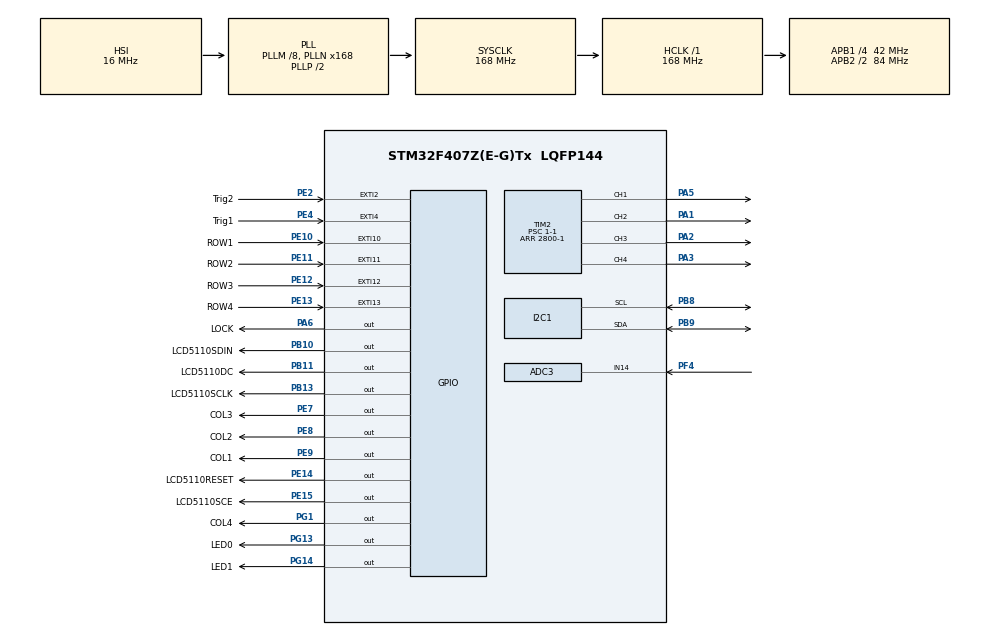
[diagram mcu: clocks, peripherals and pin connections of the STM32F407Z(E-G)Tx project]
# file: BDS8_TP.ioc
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ADC1.Channel-25\#ChannelRegularConversion=ADC_CHANNEL_VREFINT
ADC1.ClockPrescaler=ADC_CLOCK_SYNC_PCLK_DIV6
ADC1.ContinuousConvMode=ENABLE
ADC1.DMAContinuousRequests=ENABLE
ADC1.ExternalTrigConv=ADC_EXTERNALTRIGCONV_T3_TRGO
ADC1.ExternalTrigConvEdge=ADC_EXTERNALTRIGCONVEDGE_FALLING
ADC1.Mode=__NULL
ADC1.NbrOfConversionFlag=1
ADC1.Rank-25\#ChannelRegularConversion=1
ADC1.SamplingTime-25\#ChannelRegularConversion=ADC_SAMPLETIME_480CYCLES
ADC1.ScanConvMode=ENABLE
ADC1.master=1
ADC3.Channel-0\#ChannelRegularConversion=ADC_CHANNEL_14
ADC3.ClockPrescaler=ADC_CLOCK_SYNC_PCLK_DIV6
ADC3.DMAContinuousRequests=ENABLE
ADC3.ExternalTrigConv=ADC_EXTERNALTRIGCONV_T3_TRGO
ADC3.ExternalTrigConvEdge=ADC_EXTERNALTRIGCONVEDGE_FALLING
ADC3.NbrOfConversionFlag=1
ADC3.Rank-0\#ChannelRegularConversion=1
ADC3.SamplingTime-0\#ChannelRegularConversion=ADC_SAMPLETIME_480CYCLES
ADC3.ScanConvMode=ENABLE
Dma.ADC1.0.Direction=DMA_PERIPH_TO_MEMORY
Dma.ADC1.0.FIFOMode=DMA_FIFOMODE_DISABLE
Dma.ADC1.0.Instance=DMA2_Stream4
Dma.ADC1.0.MemDataAlignment=DMA_MDATAALIGN_WORD
Dma.ADC1.0.MemInc=DMA_MINC_ENABLE
Dma.ADC1.0.Mode=DMA_CIRCULAR
Dma.ADC1.0.PeriphDataAlignment=DMA_PDATAALIGN_WORD
Dma.ADC1.0.PeriphInc=DMA_PINC_DISABLE
Dma.ADC1.0.Priority=DMA_PRIORITY_VERY_HIGH
Dma.ADC3.1.Direction=DMA_PERIPH_TO_MEMORY
Dma.ADC3.1.FIFOMode=DMA_FIFOMODE_DISABLE
Dma.ADC3.1.Instance=DMA2_Stream0
Dma.ADC3.1.MemDataAlignment=DMA_MDATAALIGN_WORD
Dma.ADC3.1.MemInc=DMA_MINC_ENABLE
Dma.ADC3.1.Mode=DMA_CIRCULAR
Dma.ADC3.1.PeriphDataAlignment=DMA_PDATAALIGN_WORD
Dma.ADC3.1.PeriphInc=DMA_PINC_DISABLE
Dma.ADC3.1.Priority=DMA_PRIORITY_LOW
Dma.Request0=ADC1
Dma.Request1=ADC3
I2C1.I2C_Mode=I2C_Fast
Mcu.Family=STM32F4
Mcu.Name=STM32F407Z(E-G)Tx
Mcu.Package=LQFP144
NVIC.EXTI15_10_IRQn=true\:0\:0\:false\:false\:true\:true\:true
NVIC.EXTI2_IRQn=true\:0\:0\:false\:false\:true\:true\:true
NVIC.EXTI4_IRQn=true\:0\:0\:false\:false\:true\:true\:true
NVIC.PriorityGroup=NVIC_PRIORITYGROUP_2
NVIC.TIM2_IRQn=true\:0\:0\:false\:false\:true\:true\:true
NVIC.TIM3_IRQn=true\:1\:0\:true\:false\:true\:true\:true
PA1.GPIO_PuPd=GPIO_NOPULL
PA1.GPIO_Speed=GPIO_SPEED_FREQ_LOW
PA1.Signal=S_TIM2_CH2
PA13.Mode=Serial_Wire
PA13.Signal=SYS_JTMS-SWDIO
PA14.Mode=Serial_Wire
PA14.Signal=SYS_JTCK-SWCLK
PA2.GPIO_PuPd=GPIO_NOPULL
PA2.GPIO_Speed=GPIO_SPEED_FREQ_LOW
PA2.Signal=S_TIM2_CH3
PA3.Signal=S_TIM2_CH4
PA5.GPIO_PuPd=GPIO_NOPULL
PA5.GPIO_Speed=GPIO_SPEED_FREQ_LOW
PA5.Signal=S_TIM2_CH1_ETR
PA6.GPIO_Label=LOCK
PA6.PinState=GPIO_PIN_SET
PA6.Signal=GPIO_Output
PB10.GPIO_Label=LCD5110SDIN
PB10.GPIO_Speed=GPIO_SPEED_FREQ_VERY_HIGH
PB10.Signal=GPIO_Output
PB11.GPIO_Label=LCD5110DC
PB11.GPIO_Speed=GPIO_SPEED_FREQ_VERY_HIGH
PB11.Signal=GPIO_Output
PB13.GPIO_Label=LCD5110SCLK
PB13.GPIO_Speed=GPIO_SPEED_FREQ_VERY_HIGH
PB13.Signal=GPIO_Output
PB8.Mode=I2C
PB8.Signal=I2C1_SCL
PB9.Mode=I2C
PB9.Signal=I2C1_SDA
PC14-OSC32_IN.Mode=LSE-External-Oscillator
PC14-OSC32_IN.Signal=RCC_OSC32_IN
PC15-OSC32_OUT.Mode=LSE-External-Oscillator
PC15-OSC32_OUT.Signal=RCC_OSC32_OUT
PE10.GPIO_Label=ROW1
PE10.GPIO_ModeDefaultEXTI=GPIO_MODE_IT_FALLING
PE10.GPIO_PuPd=GPIO_PULLUP
PE10.Signal=GPXTI10
PE11.GPIO_Label=ROW2
PE11.GPIO_ModeDefaultEXTI=GPIO_MODE_IT_FALLING
PE11.GPIO_PuPd=GPIO_PULLUP
PE11.Signal=GPXTI11
PE12.GPIO_Label=ROW3
PE12.GPIO_ModeDefaultEXTI=GPIO_MODE_IT_FALLING
PE12.GPIO_PuPd=GPIO_PULLUP
PE12.Signal=GPXTI12
PE13.GPIO_Label=ROW4
PE13.GPIO_ModeDefaultEXTI=GPIO_MODE_IT_FALLING
PE13.GPIO_PuPd=GPIO_PULLUP
PE13.Signal=GPXTI13
PE14.GPIO_Label=LCD5110RESET
PE14.GPIO_Speed=GPIO_SPEED_FREQ_VERY_HIGH
PE14.Signal=GPIO_Output
PE15.GPIO_Label=LCD5110SCE
PE15.GPIO_PuPd=GPIO_PULLUP
PE15.GPIO_Speed=GPIO_SPEED_FREQ_VERY_HIGH
PE15.PinState=GPIO_PIN_SET
PE15.Signal=GPIO_Output
PE2.GPIO_Label=Trig2
PE2.GPIO_ModeDefaultEXTI=GPIO_MODE_IT_RISING
PE2.GPIO_PuPd=GPIO_PULLDOWN
PE2.Signal=GPXTI2
PE4.GPIO_Label=Trig1
PE4.GPIO_ModeDefaultEXTI=GPIO_MODE_IT_RISING
PE4.GPIO_PuPd=GPIO_PULLDOWN
PE4.Signal=GPXTI4
PE7.GPIO_Label=COL3
PE7.GPIO_PuPd=GPIO_PULLDOWN
PE7.Signal=GPIO_Output
PE8.GPIO_Label=COL2
PE8.GPIO_PuPd=GPIO_PULLDOWN
PE8.Signal=GPIO_Output
PE9.GPIO_Label=COL1
PE9.GPIO_PuPd=GPIO_PULLDOWN
PE9.Signal=GPIO_Output
PF4.Mode=IN14
PF4.Signal=ADC3_IN14
PG1.GPIO_Label=COL4
PG1.GPIO_PuPd=GPIO_PULLDOWN
PG1.Signal=GPIO_Output
PG13.GPIO_Label=LED0
PG13.GPIO_PuPd=GPIO_PULLUP
PG13.PinState=GPIO_PIN_SET
PG13.Signal=GPIO_Output
PG14.GPIO_Label=LED1
PG14.GPIO_PuPd=GPIO_PULLUP
PG14.PinState=GPIO_PIN_SET
PG14.Signal=GPIO_Output
PH0-OSC_IN.Mode=HSE-External-Oscillator
PH0-OSC_IN.Signal=RCC_OSC_IN
PH1-OSC_OUT.Mode=HSE-External-Oscillator
PH1-OSC_OUT.Signal=RCC_OSC_OUT
ProjectManager.HeapSize=0x200
ProjectManager.StackSize=0x400
ProjectManager.TargetToolchain=STM32CubeIDE
RCC.48MHZClocksFreq_Value=84000000
RCC.AHBFreq_Value=168000000
RCC.APB1CLKDivider=RCC_HCLK_DIV4
RCC.APB1Freq_Value=42000000
RCC.APB1TimFreq_Value=84000000
RCC.APB2CLKDivider=RCC_HCLK_DIV2
RCC.APB2Freq_Value=84000000
RCC.APB2TimFreq_Value=168000000
RCC.CortexFreq_Value=168000000
RCC.HCLKFreq_Value=168000000
RCC.HSE_VALUE=8000000
RCC.HSI_VALUE=16000000
RCC.PLLM=8
RCC.PLLN=168
RCC.SYSCLKFreq_VALUE=168000000
RCC.SYSCLKSource=RCC_SYSCLKSOURCE_PLLCLK
RCC.VCOOutputFreq_Value=336000000
SH.S_TIM2_CH1_ETR.0=TIM2_CH1,PWM Generation1 CH1
SH.S_TIM2_CH2.0=TIM2_CH2,PWM Generation2 CH2
SH.S_TIM2_CH3.0=TIM2_CH3,PWM Generation3 CH3
SH.S_TIM2_CH4.0=TIM2_CH4,PWM Generation4 CH4
TIM2.AutoReloadPreload=TIM_AUTORELOAD_PRELOAD_DISABLE
TIM2.Channel-PWM\ Generation1\ CH1=TIM_CHANNEL_1
TIM2.Channel-PWM\ Generation2\ CH2=TIM_CHANNEL_2
TIM2.Channel-PWM\ Generation3\ CH3=TIM_CHANNEL_3
TIM2.Channel-PWM\ Generation4\ CH4=TIM_CHANNEL_4
TIM2.CounterMode=TIM_COUNTERMODE_DOWN
TIM2.OCFastMode_PWM-PWM\ Generation1\ CH1=TIM_OCFAST_DISABLE
TIM2.OCFastMode_PWM-PWM\ Generation2\ CH2=TIM_OCFAST_ENABLE
TIM2.OCFastMode_PWM-PWM\ Generation3\ CH3=TIM_OCFAST_DISABLE
TIM2.OCPolarity_2=TIM_OCPOLARITY_HIGH
TIM2.Period=2800-1
TIM2.Prescaler=1-1
TIM2.Pulse-PWM\ Generation1\ CH1=1400-1
TIM2.Pulse-PWM\ Generation2\ CH2=1400-1
TIM2.Pulse-PWM\ Generation3\ CH3=100-1
TIM2.Pulse-PWM\ Generation4\ CH4=1400-1
TIM2.TIM_MasterOutputTrigger=TIM_TRGO_UPDATE
TIM3.Period=10000-1
TIM3.Prescaler=210-1
TIM3.TIM_MasterOutputTrigger=TIM_TRGO_UPDATE
TIM5.Prescaler=84-1
VP_ADC1_Vref_Input.Mode=IN-Vrefint
VP_TIM2_VS_ClockSourceINT.Mode=Internal
VP_TIM3_VS_ClockSourceINT.Mode=Internal
VP_TIM5_VS_ClockSourceINT.Mode=Internal
board=custom

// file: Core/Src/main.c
/* USER CODE BEGIN Header */
/**
  ******************************************************************************
  * @file           : main.c
  * @brief          : Main program body
  ******************************************************************************
  * @attention
  *
  * <h2><center>&copy; Copyright (c) 2021 STMicroelectronics.
  * All rights reserved.</center></h2>
  *
  * This software component is licensed by ST under BSD 3-Clause license,
  * the "License"; You may not use this file except in compliance with the
  * License. You may obtain a copy of the License at:
  *                        opensource.org/licenses/BSD-3-Clause
  *
  ******************************************************************************
  */
/* USER CODE END Header */
#include "main.h"

/* USER CODE BEGIN Includes */
#include "lcd5510.h"
#include "arm_math.h"
#include "stdio.h"
//#include "outputdata.h"
/* USER CODE END Includes */

/* USER CODE BEGIN PD */
#define ADCTIMES 	3		//ADC采样次数or序列个数
#define ADDR_AT24C02_Write 0xA0
#define ADDR_AT24C02_Read 0xA1
/* USER CODE END PD */

ADC_HandleTypeDef hadc1;
ADC_HandleTypeDef hadc3;
DMA_HandleTypeDef hdma_adc1;
DMA_HandleTypeDef hdma_adc3;

I2C_HandleTypeDef hi2c1;

TIM_HandleTypeDef htim2;
TIM_HandleTypeDef htim3;
TIM_HandleTypeDef htim5;

/* USER CODE BEGIN PV */

arm_pid_instance_f32 DCPID;

char show0[20];
char show1[20];
char show2[20];
char show3[20];
char show4[20];
char show5[20];
unsigned char TFTshow1[20];

float32_t Zmo[3];

uint32_t ADC_Value1[10];/*电池电压电流andDCDC电压*4*/
uint32_t ADC_Value3[10];/*电池电压电流andDCDC电压*4*/

float32_t DCVSet=32.0;

int16_t PWM=100-1;

uint32_t MainTick;
uint32_t SubTick;

int16_t COSCom2_plus=45;
float32_t COSCom2=-0.25;

//Mode
/*-1 no syn
 * 0 Init
1 Befor_Grid
2 Grided
3 ShotDown*/
int8_t Mode=0;

int32_t PHASE[1]={10500};

const float COSA[]={
		1.00000000,0.99994517,0.99978068,0.99950656,0.99912283,0.99862953,0.99802673,0.99731448,0.99649286,0.99556196,0.99452190,0.99337277,0.99211470,0.99074784,0.98927233,0.98768834,
		0.98599604,0.98419561,0.98228725,0.98027117,0.97814760,0.97591676,0.97357890,0.97113428,0.96858316,0.96592583,0.96316257,0.96029369,0.95731950,0.95424033,0.95105652,0.94776841,0.94437637,0.94088077,0.93728199,0.93358043,0.92977649,0.92587058,0.92186315,0.91775463,
		0.91354546,0.90923611,0.90482705,0.90031877,0.89571176,0.89100652,0.88620358,0.88130345,0.87630668,0.87121381,0.86602540,0.86074203,0.85536426,0.84989269,0.84432793,0.83867057,0.83292124,0.82708057,0.82114921,0.81512780,0.80901699,0.80281748,0.79652992,0.79015501,
		0.78369346,0.77714596,0.77051324,0.76379603,0.75699506,0.75011107,0.74314483,0.73609709,0.72896863,0.72176023,0.71447268,0.70710678,0.69966334,0.69214317,0.68454711,0.67687597,0.66913061,0.66131187,0.65342060,0.64545769,0.63742399,0.62932039,0.62114778,0.61290705,
		0.60459911,0.59622487,0.58778525,0.57928117,0.57071357,0.56208338,0.55339155,0.54463904,0.53582679,0.52695580,0.51802701,0.50904142,0.50000000,0.49090375,0.48175367,0.47255076,0.46329604,0.45399050,0.44463518,0.43523110,0.42577929,0.41628079,0.40673664,0.39714789,
		0.38751559,0.37784079,0.36812455,0.35836795,0.34857205,0.33873792,0.32886665,0.31895931,0.30901699,0.29904079,0.28903180,0.27899111,0.26891982,0.25881905,0.24868989,0.23853346,0.22835087,0.21814324,0.20791169,0.19765734,0.18738131,0.17708474,0.16676875,0.15643447,
		0.14608303,0.13571557,0.12533323,0.11493715,0.10452846,0.09410831,0.08367784,0.07323820,0.06279052,0.05233596,0.04187565,0.03141076,0.02094242,0.01047178,0.00000000,-0.01047178,-0.02094242,-0.03141076,-0.04187565,-0.05233596,-0.06279052,-0.07323820,-0.08367784,-0.09410831,
		-0.10452846,-0.11493715,-0.12533323,-0.13571557,-0.14608303,-0.15643447,-0.16676875,-0.17708474,-0.18738131,-0.19765734,-0.20791169,-0.21814324,-0.22835087,-0.23853346,-0.24868989,-0.25881905,-0.26891982,-0.27899111,-0.28903180,-0.29904079,-0.30901699,-0.31895931,-0.32886665,-0.33873792,
		-0.34857205,-0.35836795,-0.36812455,-0.37784079,-0.38751559,-0.39714789,-0.40673664,-0.41628079,-0.42577929,-0.43523110,-0.44463518,-0.45399050,-0.46329604,-0.47255076,-0.48175367,-0.49090375,-0.50000000,-0.50904142,-0.51802701,-0.52695580,-0.53582679,-0.54463904,-0.55339155,-0.56208338,
		-0.57071357,-0.57928117,-0.58778525,-0.59622487,-0.60459911,-0.61290705,-0.62114778,-0.62932039,-0.63742399,-0.64545769,-0.65342060,-0.66131187,-0.66913061,-0.67687597,-0.68454711,-0.69214317,-0.69966334,-0.70710678,-0.71447268,-0.72176023,-0.72896863,-0.73609709,-0.74314483,-0.75011107,
		-0.75699506,-0.76379603,-0.77051324,-0.77714596,-0.78369346,-0.79015501,-0.79652992,-0.80281748,-0.80901699,-0.81512780,-0.82114921,-0.82708057,-0.83292124,-0.83867057,-0.84432793,-0.84989269,-0.85536426,-0.86074203,-0.86602540,-0.87121381,-0.87630668,-0.88130345,-0.88620358,-0.89100652,
		-0.89571176,-0.90031877,-0.90482705,-0.90923611,-0.91354546,-0.91775463,-0.92186315,-0.92587058,-0.92977649,-0.93358043,-0.93728199,-0.94088077,-0.94437637,-0.94776841,-0.95105652,-0.95424033,-0.95731950,-0.96029369,-0.96316257,-0.96592583,-0.96858316,-0.97113428,-0.97357890,-0.97591676,
		-0.97814760,-0.98027117,-0.98228725,-0.98419561,-0.98599604,-0.98768834,-0.98927233,-0.99074784,-0.99211470,-0.99337277,-0.99452190,-0.99556196,-0.99649286,-0.99731448,-0.99802673,-0.99862953,-0.99912283,-0.99950656,-0.99978068,-0.99994517,-1.00000000,-0.99994517,-0.99978068,-0.99950656,
		-0.99912283,-0.99862953,-0.99802673,-0.99731448,-0.99649286,-0.99556196,-0.99452190,-0.99337277,-0.99211470,-0.99074784,-0.98927233,-0.98768834,-0.98599604,-0.98419561,-0.98228725,-0.98027117,-0.97814760,-0.97591676,-0.97357890,-0.97113428,-0.96858316,-0.96592583,-0.96316257,-0.96029369,
		-0.95731950,-0.95424033,-0.95105652,-0.94776841,-0.94437637,-0.94088077,-0.93728199,-0.93358043,-0.92977649,-0.92587058,-0.92186315,-0.91775463,-0.91354546,-0.90923611,-0.90482705,-0.90031877,-0.89571176,-0.89100652,-0.88620358,-0.88130345,-0.87630668,-0.87121381,-0.86602540,-0.86074203,
		-0.85536426,-0.84989269,-0.84432793,-0.83867057,-0.83292124,-0.82708057,-0.82114921,-0.81512780,-0.80901699,-0.80281748,-0.79652992,-0.79015501,-0.78369346,-0.77714596,-0.77051324,-0.76379603,-0.75699506,-0.75011107,-0.74314483,-0.73609709,-0.72896863,-0.72176023,-0.71447268,-0.70710678,
		-0.69966334,-0.69214317,-0.68454711,-0.67687597,-0.66913061,-0.66131187,-0.65342060,-0.64545769,-0.63742399,-0.62932039,-0.62114778,-0.61290705,-0.60459911,-0.59622487,-0.58778525,-0.57928117,-0.57071357,-0.56208338,-0.55339155,-0.54463904,-0.53582679,-0.52695580,-0.51802701,-0.50904142,
		-0.50000000,-0.49090375,-0.48175367,-0.47255076,-0.46329604,-0.45399050,-0.44463518,-0.43523110,-0.42577929,-0.41628079,-0.40673664,-0.39714789,-0.38751559,-0.37784079,-0.36812455,-0.35836795,-0.34857205,-0.33873792,-0.32886665,-0.31895931,-0.30901699,-0.29904079,-0.28903180,-0.27899111,
		-0.26891982,-0.25881905,-0.24868989,-0.23853346,-0.22835087,-0.21814324,-0.20791169,-0.19765734,-0.18738131,-0.17708474,-0.16676875,-0.15643447,-0.14608303,-0.13571557,-0.12533323,-0.11493715,-0.10452846,-0.09410831,-0.08367784,-0.07323820,-0.06279052,-0.05233596,-0.04187565,-0.03141076,
		-0.02094242,-0.01047178,0.00000000,0.01047178,0.02094242,0.03141076,0.04187565,0.05233596,0.06279052,0.07323820,0.08367784,0.09410831,0.10452846,0.11493715,0.12533323,0.13571557,0.14608303,0.15643447,0.16676875,0.17708474,0.18738131,0.19765734,0.20791169,0.21814324,
		0.22835087,0.23853346,0.24868989,0.25881905,0.26891982,0.27899111,0.28903180,0.29904079,0.30901699,0.31895931,0.32886665,0.33873792,0.34857205,0.35836795,0.36812455,0.37784079,0.38751559,0.39714789,0.40673664,0.41628079,0.42577929,0.43523110,0.44463518,0.45399050,
		0.46329604,0.47255076,0.48175367,0.49090375,0.50000000,0.50904142,0.51802701,0.52695580,0.53582679,0.54463904,0.55339155,0.56208338,0.57071357,0.57928117,0.58778525,0.59622487,0.60459911,0.61290705,0.62114778,0.62932039,0.63742399,0.64545769,0.65342060,0.66131187,
		0.66913061,0.67687597,0.68454711,0.69214317,0.69966334,0.70710678,0.71447268,0.72176023,0.72896863,0.73609709,0.74314483,0.75011107,0.75699506,0.76379603,0.77051324,0.77714596,0.78369346,0.79015501,0.79652992,0.80281748,0.80901699,0.81512780,0.82114921,0.82708057,
		0.83292124,0.83867057,0.84432793,0.84989269,0.85536426,0.86074203,0.86602540,0.87121381,0.87630668,0.88130345,0.88620358,0.89100652,0.89571176,0.90031877,0.90482705,0.90923611,0.91354546,0.91775463,0.92186315,0.92587058,0.92977649,0.93358043,0.93728199,0.94088077,
		0.94437637,0.94776841,0.95105652,0.95424033,0.95731950,0.96029369,0.96316257,0.96592583,0.96858316,0.97113428,0.97357890,0.97591676,0.97814760,0.98027117,0.98228725,0.98419561,0.98599604,0.98768834,0.98927233,0.99074784,0.99211470,0.99337277,0.99452190,0.99556196,
		0.99649286,0.99731448,0.99802673,0.99862953,0.99912283,0.99950656,0.99978068,0.99994517
};

const float COSB[]={
		-0.50000000,-0.49090375,-0.48175367,-0.47255076,-0.46329604,-0.45399050,-0.44463518,-0.43523110,
		-0.42577929,-0.41628079,-0.40673664,-0.39714789,-0.38751559,-0.37784079,-0.36812455,-0.35836795,-0.34857205,-0.33873792,-0.32886665,-0.31895931,-0.30901699,-0.29904079,-0.28903180,-0.27899111,-0.26891982,-0.25881905,-0.24868989,-0.23853346,-0.22835087,-0.21814324,-0.20791169,-0.19765734,
		-0.18738131,-0.17708474,-0.16676875,-0.15643447,-0.14608303,-0.13571557,-0.12533323,-0.11493715,-0.10452846,-0.09410831,-0.08367784,-0.07323820,-0.06279052,-0.05233596,-0.04187565,-0.03141076,-0.02094242,-0.01047178,-0.00000000,0.01047178,0.02094242,0.03141076,0.04187565,0.05233596,
		0.06279052,0.07323820,0.08367784,0.09410831,0.10452846,0.11493715,0.12533323,0.13571557,0.14608303,0.15643447,0.16676875,0.17708474,0.18738131,0.19765734,0.20791169,0.21814324,0.22835087,0.23853346,0.24868989,0.25881905,0.26891982,0.27899111,0.28903180,0.29904079,
		0.30901699,0.31895931,0.32886665,0.33873792,0.34857205,0.35836795,0.36812455,0.37784079,0.38751559,0.39714789,0.40673664,0.41628079,0.42577929,0.43523110,0.44463518,0.45399050,0.46329604,0.47255076,0.48175367,0.49090375,0.50000000,0.50904142,0.51802701,0.52695580,
		0.53582679,0.54463904,0.55339155,0.56208338,0.57071357,0.57928117,0.58778525,0.59622487,0.60459911,0.61290705,0.62114778,0.62932039,0.63742399,0.64545769,0.65342060,0.66131187,0.66913061,0.67687597,0.68454711,0.69214317,0.69966334,0.70710678,0.71447268,0.72176023,
		0.72896863,0.73609709,0.74314483,0.75011107,0.75699506,0.76379603,0.77051324,0.77714596,0.78369346,0.79015501,0.79652992,0.80281748,0.80901699,0.81512780,0.82114921,0.82708057,0.83292124,0.83867057,0.84432793,0.84989269,0.85536426,0.86074203,0.86602540,0.87121381,
		0.87630668,0.88130345,0.88620358,0.89100652,0.89571176,0.90031877,0.90482705,0.90923611,0.91354546,0.91775463,0.92186315,0.92587058,0.92977649,0.93358043,0.93728199,0.94088077,0.94437637,0.94776841,0.95105652,0.95424033,0.95731950,0.96029369,0.96316257,0.96592583,
		0.96858316,0.97113428,0.97357890,0.97591676,0.97814760,0.98027117,0.98228725,0.98419561,0.98599604,0.98768834,0.98927233,0.99074784,0.99211470,0.99337277,0.99452190,0.99556196,0.99649286,0.99731448,0.99802673,0.99862953,0.99912283,0.99950656,0.99978068,0.99994517,
		1.00000000,0.99994517,0.99978068,0.99950656,0.99912283,0.99862953,0.99802673,0.99731448,0.99649286,0.99556196,0.99452190,0.99337277,0.99211470,0.99074784,0.98927233,0.98768834,0.98599604,0.98419561,0.98228725,0.98027117,0.97814760,0.97591676,0.97357890,0.97113428,
		0.96858316,0.96592583,0.96316257,0.96029369,0.95731950,0.95424033,0.95105652,0.94776841,0.94437637,0.94088077,0.93728199,0.93358043,0.92977649,0.92587058,0.92186315,0.91775463,0.91354546,0.90923611,0.90482705,0.90031877,0.89571176,0.89100652,0.88620358,0.88130345,
		0.87630668,0.87121381,0.86602540,0.86074203,0.85536426,0.84989269,0.84432793,0.83867057,0.83292124,0.82708057,0.82114921,0.81512780,0.80901699,0.80281748,0.79652992,0.79015501,0.78369346,0.77714596,0.77051324,0.76379603,0.75699506,0.75011107,0.74314483,0.73609709,
		0.72896863,0.72176023,0.71447268,0.70710678,0.69966334,0.69214317,0.68454711,0.67687597,0.66913061,0.66131187,0.65342060,0.64545769,0.63742399,0.62932039,0.62114778,0.61290705,0.60459911,0.59622487,0.58778525,0.57928117,0.57071357,0.56208338,0.55339155,0.54463904,
		0.53582679,0.52695580,0.51802701,0.50904142,0.50000000,0.49090375,0.48175367,0.47255076,0.46329604,0.45399050,0.44463518,0.43523110,0.42577929,0.41628079,0.40673664,0.39714789,0.38751559,0.37784079,0.36812455,0.35836795,0.34857205,0.33873792,0.32886665,0.31895931,
		0.30901699,0.29904079,0.28903180,0.27899111,0.26891982,0.25881905,0.24868989,0.23853346,0.22835087,0.21814324,0.20791169,0.19765734,0.18738131,0.17708474,0.16676875,0.15643447,0.14608303,0.13571557,0.12533323,0.11493715,0.10452846,0.09410831,0.08367784,0.07323820,
		0.06279052,0.05233596,0.04187565,0.03141076,0.02094242,0.01047178,0.00000000,-0.01047178,-0.02094242,-0.03141076,-0.04187565,-0.05233596,-0.06279052,-0.07323820,-0.08367784,-0.09410831,-0.10452846,-0.11493715,-0.12533323,-0.13571557,-0.14608303,-0.15643447,-0.16676875,-0.17708474,
		-0.18738131,-0.19765734,-0.20791169,-0.21814324,-0.22835087,-0.23853346,-0.24868989,-0.25881905,-0.26891982,-0.27899111,-0.28903180,-0.29904079,-0.30901699,-0.31895931,-0.32886665,-0.33873792,-0.34857205,-0.35836795,-0.36812455,-0.37784079,-0.38751559,-0.39714789,-0.40673664,-0.41628079,
		-0.42577929,-0.43523110,-0.44463518,-0.45399050,-0.46329604,-0.47255076,-0.48175367,-0.49090375,-0.50000000,-0.50904142,-0.51802701,-0.52695580,-0.53582679,-0.54463904,-0.55339155,-0.56208338,-0.57071357,-0.57928117,-0.58778525,-0.59622487,-0.60459911,-0.61290705,-0.62114778,-0.62932039,
		-0.63742399,-0.64545769,-0.65342060,-0.66131187,-0.66913061,-0.67687597,-0.68454711,-0.69214317,-0.69966334,-0.70710678,-0.71447268,-0.72176023,-0.72896863,-0.73609709,-0.74314483,-0.75011107,-0.75699506,-0.76379603,-0.77051324,-0.77714596,-0.78369346,-0.79015501,-0.79652992,-0.80281748,
		-0.80901699,-0.81512780,-0.82114921,-0.82708057,-0.83292124,-0.83867057,-0.84432793,-0.84989269,-0.85536426,-0.86074203,-0.86602540,-0.87121381,-0.87630668,-0.88130345,-0.88620358,-0.89100652,-0.89571176,-0.90031877,-0.90482705,-0.90923611,-0.91354546,-0.91775463,-0.92186315,-0.92587058,
		-0.92977649,-0.93358043,-0.93728199,-0.94088077,-0.94437637,-0.94776841,-0.95105652,-0.95424033,-0.95731950,-0.96029369,-0.96316257,-0.96592583,-0.96858316,-0.97113428,-0.97357890,-0.97591676,-0.97814760,-0.98027117,-0.98228725,-0.98419561,-0.98599604,-0.98768834,-0.98927233,-0.99074784,
		-0.99211470,-0.99337277,-0.99452190,-0.99556196,-0.99649286,-0.99731448,-0.99802673,-0.99862953,-0.99912283,-0.99950656,-0.99978068,-0.99994517,-1.00000000,-0.99994517,-0.99978068,-0.99950656,-0.99912283,-0.99862953,-0.99802673,-0.99731448,-0.99649286,-0.99556196,-0.99452190,-0.99337277,
		-0.99211470,-0.99074784,-0.98927233,-0.98768834,-0.98599604,-0.98419561,-0.98228725,-0.98027117,-0.97814760,-0.97591676,-0.97357890,-0.97113428,-0.96858316,-0.96592583,-0.96316257,-0.96029369,-0.95731950,-0.95424033,-0.95105652,-0.94776841,-0.94437637,-0.94088077,-0.93728199,-0.93358043,
		-0.92977649,-0.92587058,-0.92186315,-0.91775463,-0.91354546,-0.90923611,-0.90482705,-0.90031877,-0.89571176,-0.89100652,-0.88620358,-0.88130345,-0.87630668,-0.87121381,-0.86602540,-0.86074203,-0.85536426,-0.84989269,-0.84432793,-0.83867057,-0.83292124,-0.82708057,-0.82114921,-0.81512780,
		-0.80901699,-0.80281748,-0.79652992,-0.79015501,-0.78369346,-0.77714596,-0.77051324,-0.76379603,-0.75699506,-0.75011107,-0.74314483,-0.73609709,-0.72896863,-0.72176023,-0.71447268,-0.70710678,-0.69966334,-0.69214317,-0.68454711,-0.67687597,-0.66913061,-0.66131187,-0.65342060,-0.64545769,
		-0.63742399,-0.62932039,-0.62114778,-0.61290705,-0.60459911,-0.59622487,-0.58778525,-0.57928117,-0.57071357,-0.56208338,-0.55339155,-0.54463904,-0.53582679,-0.52695580,-0.51802701,-0.50904142,
};

const float COSC[]={
		-0.50000000,-0.50904142,-0.51802701,-0.52695580,-0.53582679,-0.54463904,-0.55339155,-0.56208338,-0.57071357,-0.57928117,-0.58778525,-0.59622487,-0.60459911,-0.61290705,-0.62114778,-0.62932039,-0.63742399,-0.64545769,-0.65342060,-0.66131187,-0.66913061,-0.67687597,-0.68454711,-0.69214317,
		-0.69966334,-0.70710678,-0.71447268,-0.72176023,-0.72896863,-0.73609709,-0.74314483,-0.75011107,-0.75699506,-0.76379603,-0.77051324,-0.77714596,-0.78369346,-0.79015501,-0.79652992,-0.80281748,-0.80901699,-0.81512780,-0.82114921,-0.82708057,-0.83292124,-0.83867057,-0.84432793,-0.84989269,
		-0.85536426,-0.86074203,-0.86602540,-0.87121381,-0.87630668,-0.88130345,-0.88620358,-0.89100652,-0.89571176,-0.90031877,-0.90482705,-0.90923611,-0.91354546,-0.91775463,-0.92186315,-0.92587058,-0.92977649,-0.93358043,-0.93728199,-0.94088077,-0.94437637,-0.94776841,-0.95105652,-0.95424033,
		-0.95731950,-0.96029369,-0.96316257,-0.96592583,-0.96858316,-0.97113428,-0.97357890,-0.97591676,-0.97814760,-0.98027117,-0.98228725,-0.98419561,-0.98599604,-0.98768834,-0.98927233,-0.99074784,-0.99211470,-0.99337277,-0.99452190,-0.99556196,-0.99649286,-0.99731448,-0.99802673,-0.99862953,
		-0.99912283,-0.99950656,-0.99978068,-0.99994517,-1.00000000,-0.99994517,-0.99978068,-0.99950656,-0.99912283,-0.99862953,-0.99802673,-0.99731448,-0.99649286,-0.99556196,-0.99452190,-0.99337277,-0.99211470,-0.99074784,-0.98927233,-0.98768834,-0.98599604,-0.98419561,-0.98228725,-0.98027117,
		-0.97814760,-0.97591676,-0.97357890,-0.97113428,-0.96858316,-0.96592583,-0.96316257,-0.96029369,-0.95731950,-0.95424033,-0.95105652,-0.94776841,-0.94437637,-0.94088077,-0.93728199,-0.93358043,-0.92977649,-0.92587058,-0.92186315,-0.91775463,-0.91354546,-0.90923611,-0.90482705,-0.90031877,
		-0.89571176,-0.89100652,-0.88620358,-0.88130345,-0.87630668,-0.87121381,-0.86602540,-0.86074203,-0.85536426,-0.84989269,-0.84432793,-0.83867057,-0.83292124,-0.82708057,-0.82114921,-0.81512780,-0.80901699,-0.80281748,-0.79652992,-0.79015501,-0.78369346,-0.77714596,-0.77051324,-0.76379603,
		-0.75699506,-0.75011107,-0.74314483,-0.73609709,-0.72896863,-0.72176023,-0.71447268,-0.70710678,-0.69966334,-0.69214317,-0.68454711,-0.67687597,-0.66913061,-0.66131187,-0.65342060,-0.64545769,-0.63742399,-0.62932039,-0.62114778,-0.61290705,-0.60459911,-0.59622487,-0.58778525,-0.57928117,
		-0.57071357,-0.56208338,-0.55339155,-0.54463904,-0.53582679,-0.52695580,-0.51802701,-0.50904142,-0.50000000,-0.49090375,-0.48175367,-0.47255076,-0.46329604,-0.45399050,-0.44463518,-0.43523110,-0.42577929,-0.41628079,-0.40673664,-0.39714789,-0.38751559,-0.37784079,-0.36812455,-0.35836795,
		-0.34857205,-0.33873792,-0.32886665,-0.31895931,-0.30901699,-0.29904079,-0.28903180,-0.27899111,-0.26891982,-0.25881905,-0.24868989,-0.23853346,-0.22835087,-0.21814324,-0.20791169,-0.19765734,-0.18738131,-0.17708474,-0.16676875,-0.15643447,-0.14608303,-0.13571557,-0.12533323,-0.11493715,
		-0.10452846,-0.09410831,-0.08367784,-0.07323820,-0.06279052,-0.05233596,-0.04187565,-0.03141076,-0.02094242,-0.01047178,-0.00000000,0.01047178,0.02094242,0.03141076,0.04187565,0.05233596,0.06279052,0.07323820,0.08367784,0.09410831,0.10452846,0.11493715,0.12533323,0.13571557,
		0.14608303,0.15643447,0.16676875,0.17708474,0.18738131,0.19765734,0.20791169,0.21814324,0.22835087,0.23853346,0.24868989,0.25881905,0.26891982,0.27899111,0.28903180,0.29904079,0.30901699,0.31895931,0.32886665,0.33873792,0.34857205,0.35836795,0.36812455,0.37784079,
		0.38751559,0.39714789,0.40673664,0.41628079,0.42577929,0.43523110,0.44463518,0.45399050,0.46329604,0.47255076,0.48175367,0.49090375,0.50000000,0.50904142,0.51802701,0.52695580,0.53582679,0.54463904,0.55339155,0.56208338,0.57071357,0.57928117,0.58778525,0.59622487,
		0.60459911,0.61290705,0.62114778,0.62932039,0.63742399,0.64545769,0.65342060,0.66131187,0.66913061,0.67687597,0.68454711,0.69214317,0.69966334,0.70710678,0.71447268,0.72176023,0.72896863,0.73609709,0.74314483,0.75011107,0.75699506,0.76379603,0.77051324,0.77714596,
		0.78369346,0.79015501,0.79652992,0.80281748,0.80901699,0.81512780,0.82114921,0.82708057,0.83292124,0.83867057,0.84432793,0.84989269,0.85536426,0.86074203,0.86602540,0.87121381,0.87630668,0.88130345,0.88620358,0.89100652,0.89571176,0.90031877,0.90482705,0.90923611,
		0.91354546,0.91775463,0.92186315,0.92587058,0.92977649,0.93358043,0.93728199,0.94088077,0.94437637,0.94776841,0.95105652,0.95424033,0.95731950,0.96029369,0.96316257,0.96592583,0.96858316,0.97113428,0.97357890,0.97591676,0.97814760,0.98027117,0.98228725,0.98419561,
		0.98599604,0.98768834,0.98927233,0.99074784,0.99211470,0.99337277,0.99452190,0.99556196,0.99649286,0.99731448,0.99802673,0.99862953,0.99912283,0.99950656,0.99978068,0.99994517,1.00000000,0.99994517,0.99978068,0.99950656,0.99912283,0.99862953,0.99802673,0.99731448,
		0.99649286,0.99556196,0.99452190,0.99337277,0.99211470,0.99074784,0.98927233,0.98768834,0.98599604,0.98419561,0.98228725,0.98027117,0.97814760,0.97591676,0.97357890,0.97113428,0.96858316,0.96592583,0.96316257,0.96029369,0.95731950,0.95424033,0.95105652,0.94776841,
		0.94437637,0.94088077,0.93728199,0.93358043,0.92977649,0.92587058,0.92186315,0.91775463,0.91354546,0.90923611,0.90482705,0.90031877,0.89571176,0.89100652,0.88620358,0.88130345,0.87630668,0.87121381,0.86602540,0.86074203,0.85536426,0.84989269,0.84432793,0.83867057,
		0.83292124,0.82708057,0.82114921,0.81512780,0.80901699,0.80281748,0.79652992,0.79015501,0.78369346,0.77714596,0.77051324,0.76379603,0.75699506,0.75011107,0.74314483,0.73609709,0.72896863,0.72176023,0.71447268,0.70710678,0.69966334,0.69214317,0.68454711,0.67687597,
		0.66913061,0.66131187,0.65342060,0.64545769,0.63742399,0.62932039,0.62114778,0.61290705,0.60459911,0.59622487,0.58778525,0.57928117,0.57071357,0.56208338,0.55339155,0.54463904,0.53582679,0.52695580,0.51802701,0.50904142,0.50000000,0.49090375,0.48175367,0.47255076,
		0.46329604,0.45399050,0.44463518,0.43523110,0.42577929,0.41628079,0.40673664,0.39714789,0.38751559,0.37784079,0.36812455,0.35836795,0.34857205,0.33873792,0.32886665,0.31895931,0.30901699,0.29904079,0.28903180,0.27899111,0.26891982,0.25881905,0.24868989,0.23853346,
		0.22835087,0.21814324,0.20791169,0.19765734,0.18738131,0.17708474,0.16676875,0.15643447,0.14608303,0.13571557,0.12533323,0.11493715,0.10452846,0.09410831,0.08367784,0.07323820,0.06279052,0.05233596,0.04187565,0.03141076,0.02094242,0.01047178,0.00000000,-0.01047178,
		-0.02094242,-0.03141076,-0.04187565,-0.05233596,-0.06279052,-0.07323820,-0.08367784,-0.09410831,-0.10452846,-0.11493715,-0.12533323,-0.13571557,-0.14608303,-0.15643447,-0.16676875,-0.17708474,-0.18738131,-0.19765734,-0.20791169,-0.21814324,-0.22835087,-0.23853346,-0.24868989,-0.25881905,
		-0.26891982,-0.27899111,-0.28903180,-0.29904079,-0.30901699,-0.31895931,-0.32886665,-0.33873792,-0.34857205,-0.35836795,-0.36812455,-0.37784079,-0.38751559,-0.39714789,-0.40673664,-0.41628079,-0.42577929,-0.43523110,-0.44463518,-0.45399050,-0.46329604,-0.47255076,-0.48175367,-0.49090375
};

const float COSS[]={
		-1.00000000,-0.99950656,-0.99802673,-0.99556196,-0.99211470,-0.98768834,-0.98228725,-0.97591676,-0.96858316,-0.96029369,
		-0.95105652,-0.94088077,-0.92977649,-0.91775463,-0.90482705,-0.89100652,-0.87630668,-0.86074203,-0.84432793,-0.82708057,-0.80901699,-0.79015501,-0.77051324,-0.75011107,-0.72896863,-0.70710678,-0.68454711,-0.66131187,-0.63742399,-0.61290705,
		-0.58778525,-0.56208338,-0.53582679,-0.50904142,-0.48175367,-0.45399050,-0.42577929,-0.39714789,-0.36812455,-0.33873792,-0.30901699,-0.27899111,-0.24868989,-0.21814324,-0.18738131,-0.15643447,-0.12533323,-0.09410831,-0.06279052,-0.03141076,
		0.00000000,0.03141076,0.06279052,0.09410831,0.12533323,0.15643447,0.18738131,0.21814324,0.24868989,0.27899111,0.30901699,0.33873792,0.36812455,0.39714789,0.42577929,0.45399050,0.48175367,0.50904142,0.53582679,0.56208338,
		0.58778525,0.61290705,0.63742399,0.66131187,0.68454711,0.70710678,0.72896863,0.75011107,0.77051324,0.79015501,0.80901699,0.82708057,0.84432793,0.86074203,0.87630668,0.89100652,0.90482705,0.91775463,0.92977649,0.94088077,
		0.95105652,0.96029369,0.96858316,0.97591676,0.98228725,0.98768834,0.99211470,0.99556196,0.99802673,0.99950656,1.00000000,0.99950656,0.99802673,0.99556196,0.99211470,0.98768834,0.98228725,0.97591676,0.96858316,0.96029369,
		0.95105652,0.94088077,0.92977649,0.91775463,0.90482705,0.89100652,0.87630668,0.86074203,0.84432793,0.82708057,0.80901699,0.79015501,0.77051324,0.75011107,0.72896863,0.70710678,0.68454711,0.66131187,0.63742399,0.61290705,
		0.58778525,0.56208338,0.53582679,0.50904142,0.48175367,0.45399050,0.42577929,0.39714789,0.36812455,0.33873792,0.30901699,0.27899111,0.24868989,0.21814324,0.18738131,0.15643447,0.12533323,0.09410831,0.06279052,0.03141076,
		0.00000000,-0.03141076,-0.06279052,-0.09410831,-0.12533323,-0.15643447,-0.18738131,-0.21814324,-0.24868989,-0.27899111,-0.30901699,-0.33873792,-0.36812455,-0.39714789,-0.42577929,-0.45399050,-0.48175367,-0.50904142,-0.53582679,-0.56208338,
		-0.58778525,-0.61290705,-0.63742399,-0.66131187,-0.68454711,-0.70710678,-0.72896863,-0.75011107,-0.77051324,-0.79015501,-0.80901699,-0.82708057,-0.84432793,-0.86074203,-0.87630668,-0.89100652,-0.90482705,-0.91775463,-0.92977649,-0.94088077,
		-0.95105652,-0.96029369,-0.96858316,-0.97591676,-0.98228725,-0.98768834,-0.99211470,-0.99556196,-0.99802673,-0.99950656,-1.00000000,-0.99950656,-0.99802673,-0.99556196,-0.99211470,-0.98768834,-0.98228725,-0.97591676,-0.96858316,-0.96029369,
		-0.95105652,-0.94088077,-0.92977649,-0.91775463,-0.90482705,-0.89100652,-0.87630668,-0.86074203,-0.84432793,-0.82708057,-0.80901699,-0.79015501,-0.77051324,-0.75011107,-0.72896863,-0.70710678,-0.68454711,-0.66131187,-0.63742399,-0.61290705,
		-0.58778525,-0.56208338,-0.53582679,-0.50904142,-0.48175367,-0.45399050,-0.42577929,-0.39714789,-0.36812455,-0.33873792,-0.30901699,-0.27899111,-0.24868989,-0.21814324,-0.18738131,-0.15643447,-0.12533323,-0.09410831,-0.06279052,-0.03141076,
		0.00000000,0.03141076,0.06279052,0.09410831,0.12533323,0.15643447,0.18738131,0.21814324,0.24868989,0.27899111,0.30901699,0.33873792,0.36812455,0.39714789,0.42577929,0.45399050,0.48175367,0.50904142,0.53582679,0.56208338,
		0.58778525,0.61290705,0.63742399,0.66131187,0.68454711,0.70710678,0.72896863,0.75011107,0.77051324,0.79015501,0.80901699,0.82708057,0.84432793,0.86074203,0.87630668,0.89100652,0.90482705,0.91775463,0.92977649,0.94088077,
		0.95105652,0.96029369,0.96858316,0.97591676,0.98228725,0.98768834,0.99211470,0.99556196,0.99802673,0.99950656,1.00000000,0.99950656,0.99802673,0.99556196,0.99211470,0.98768834,0.98228725,0.97591676,0.96858316,0.96029369,
		0.95105652,0.94088077,0.92977649,0.91775463,0.90482705,0.89100652,0.87630668,0.86074203,0.84432793,0.82708057,0.80901699,0.79015501,0.77051324,0.75011107,0.72896863,0.70710678,0.68454711,0.66131187,0.63742399,0.61290705,
		0.58778525,0.56208338,0.53582679,0.50904142,0.48175367,0.45399050,0.42577929,0.39714789,0.36812455,0.33873792,0.30901699,0.27899111,0.24868989,0.21814324,0.18738131,0.15643447,0.12533323,0.09410831,0.06279052,0.03141076,
		0.00000000,-0.03141076,-0.06279052,-0.09410831,-0.12533323,-0.15643447,-0.18738131,-0.21814324,-0.24868989,-0.27899111,-0.30901699,-0.33873792,-0.36812455,-0.39714789,-0.42577929,-0.45399050,-0.48175367,-0.50904142,-0.53582679,-0.56208338,
		-0.58778525,-0.61290705,-0.63742399,-0.66131187,-0.68454711,-0.70710678,-0.72896863,-0.75011107,-0.77051324,-0.79015501,-0.80901699,-0.82708057,-0.84432793,-0.86074203,-0.87630668,-0.89100652,-0.90482705,-0.91775463,-0.92977649,-0.94088077,
		-0.95105652,-0.96029369,-0.96858316,-0.97591676,-0.98228725,-0.98768834,-0.99211470,-0.99556196,-0.99802673,-0.99950656,-1.00000000,-0.99950656,-0.99802673,-0.99556196,-0.99211470,-0.98768834,-0.98228725,-0.97591676,-0.96858316,-0.96029369,
		-0.95105652,-0.94088077,-0.92977649,-0.91775463,-0.90482705,-0.89100652,-0.87630668,-0.86074203,-0.84432793,-0.82708057,-0.80901699,-0.79015501,-0.77051324,-0.75011107,-0.72896863,-0.70710678,-0.68454711,-0.66131187,-0.63742399,-0.61290705,
		-0.58778525,-0.56208338,-0.53582679,-0.50904142,-0.48175367,-0.45399050,-0.42577929,-0.39714789,-0.36812455,-0.33873792,-0.30901699,-0.27899111,-0.24868989,-0.21814324,-0.18738131,-0.15643447,-0.12533323,-0.09410831,-0.06279052,-0.03141076,
		0.00000000,0.03141076,0.06279052,0.09410831,0.12533323,0.15643447,0.18738131,0.21814324,0.24868989,0.27899111,0.30901699,0.33873792,0.36812455,0.39714789,0.42577929,0.45399050,0.48175367,0.50904142,0.53582679,0.56208338,
		0.58778525,0.61290705,0.63742399,0.66131187,0.68454711,0.70710678,0.72896863,0.75011107,0.77051324,0.79015501,0.80901699,0.82708057,0.84432793,0.86074203,0.87630668,0.89100652,0.90482705,0.91775463,0.92977649,0.94088077,
		0.95105652,0.96029369,0.96858316,0.97591676,0.98228725,0.98768834,0.99211470,0.99556196,0.99802673,0.99950656,1.00000000,0.99950656,0.99802673,0.99556196,0.99211470,0.98768834,0.98228725,0.97591676,0.96858316,0.96029369,
		0.95105652,0.94088077,0.92977649,0.91775463,0.90482705,0.89100652,0.87630668,0.86074203,0.84432793,0.82708057,0.80901699,0.79015501,0.77051324,0.75011107,0.72896863,0.70710678,0.68454711,0.66131187,0.63742399,0.61290705,
		0.58778525,0.56208338,0.53582679,0.50904142,0.48175367,0.45399050,0.42577929,0.39714789,0.36812455,0.33873792,0.30901699,0.27899111,0.24868989,0.21814324,0.18738131,0.15643447,0.12533323,0.09410831,0.06279052,0.03141076,
		0.00000000,-0.03141076,-0.06279052,-0.09410831,-0.12533323,-0.15643447,-0.18738131,-0.21814324,-0.24868989,-0.27899111,-0.30901699,-0.33873792,-0.36812455,-0.39714789,-0.42577929,-0.45399050,-0.48175367,-0.50904142,-0.53582679,-0.56208338,
		-0.58778525,-0.61290705,-0.63742399,-0.66131187,-0.68454711,-0.70710678,-0.72896863,-0.75011107,-0.77051324,-0.79015501,-0.80901699,-0.82708057,-0.84432793,-0.86074203,-0.87630668,-0.89100652,-0.90482705,-0.91775463,-0.92977649,-0.94088077,
		-0.95105652,-0.96029369,-0.96858316,-0.97591676,-0.98228725,-0.98768834,-0.99211470,-0.99556196,-0.99802673,-0.99950656
};

const float COSS2[]={
1.00000000,0.99862953,0.99452190,0.98768834,0.97814760,0.96592583,0.95105652,0.93358043,0.91354546,0.89100652,
0.86602540,0.83867057,0.80901699,0.77714596,0.74314483,0.70710678,0.66913061,0.62932039,0.58778525,0.54463904,0.50000000,0.45399050,0.40673664,0.35836795,0.30901699,0.25881905,0.20791169,0.15643447,0.10452846,0.05233596,
0.00000000,-0.05233596,-0.10452846,-0.15643447,-0.20791169,-0.25881905,-0.30901699,-0.35836795,-0.40673664,-0.45399050,-0.50000000,-0.54463904,-0.58778525,-0.62932039,-0.66913061,-0.70710678,-0.74314483,-0.77714596,-0.80901699,-0.83867057,
-0.86602540,-0.89100652,-0.91354546,-0.93358043,-0.95105652,-0.96592583,-0.97814760,-0.98768834,-0.99452190,-0.99862953,-1.00000000,-0.99862953,-0.99452190,-0.98768834,-0.97814760,-0.96592583,-0.95105652,-0.93358043,-0.91354546,-0.89100652,
-0.86602540,-0.83867057,-0.80901699,-0.77714596,-0.74314483,-0.70710678,-0.66913061,-0.62932039,-0.58778525,-0.54463904,-0.50000000,-0.45399050,-0.40673664,-0.35836795,-0.30901699,-0.25881905,-0.20791169,-0.15643447,-0.10452846,-0.05233596,
0.00000000,0.05233596,0.10452846,0.15643447,0.20791169,0.25881905,0.30901699,0.35836795,0.40673664,0.45399050,0.50000000,0.54463904,0.58778525,0.62932039,0.66913061,0.70710678,0.74314483,0.77714596,0.80901699,0.83867057,
0.86602540,0.89100652,0.91354546,0.93358043,0.95105652,0.96592583,0.97814760,0.98768834,0.99452190,0.99862953,1.00000000,0.99862953,0.99452190,0.98768834,0.97814760,0.96592583,0.95105652,0.93358043,0.91354546,0.89100652,
0.86602540,0.83867057,0.80901699,0.77714596,0.74314483,0.70710678,0.66913061,0.62932039,0.58778525,0.54463904,0.50000000,0.45399050,0.40673664,0.35836795,0.30901699,0.25881905,0.20791169,0.15643447,0.10452846,0.05233596,
0.00000000,-0.05233596,-0.10452846,-0.15643447,-0.20791169,-0.25881905,-0.30901699,-0.35836795,-0.40673664,-0.45399050,-0.50000000,-0.54463904,-0.58778525,-0.62932039,-0.66913061,-0.70710678,-0.74314483,-0.77714596,-0.80901699,-0.83867057,
-0.86602540,-0.89100652,-0.91354546,-0.93358043,-0.95105652,-0.96592583,-0.97814760,-0.98768834,-0.99452190,-0.99862953,-1.00000000,-0.99862953,-0.99452190,-0.98768834,-0.97814760,-0.96592583,-0.95105652,-0.93358043,-0.91354546,-0.89100652,
-0.86602540,-0.83867057,-0.80901699,-0.77714596,-0.74314483,-0.70710678,-0.66913061,-0.62932039,-0.58778525,-0.54463904,-0.50000000,-0.45399050,-0.40673664,-0.35836795,-0.30901699,-0.25881905,-0.20791169,-0.15643447,-0.10452846,-0.05233596,
0.00000000,0.05233596,0.10452846,0.15643447,0.20791169,0.25881905,0.30901699,0.35836795,0.40673664,0.45399050,0.50000000,0.54463904,0.58778525,0.62932039,0.66913061,0.70710678,0.74314483,0.77714596,0.80901699,0.83867057,
0.86602540,0.89100652,0.91354546,0.93358043,0.95105652,0.96592583,0.97814760,0.98768834,0.99452190,0.99862953,1.00000000,0.99862953,0.99452190,0.98768834,0.97814760,0.96592583,0.95105652,0.93358043,0.91354546,0.89100652,
0.86602540,0.83867057,0.80901699,0.77714596,0.74314483,0.70710678,0.66913061,0.62932039,0.58778525,0.54463904,0.50000000,0.45399050,0.40673664,0.35836795,0.30901699,0.25881905,0.20791169,0.15643447,0.10452846,0.05233596,
0.00000000,-0.05233596,-0.10452846,-0.15643447,-0.20791169,-0.25881905,-0.30901699,-0.35836795,-0.40673664,-0.45399050,-0.50000000,-0.54463904,-0.58778525,-0.62932039,-0.66913061,-0.70710678,-0.74314483,-0.77714596,-0.80901699,-0.83867057,
-0.86602540,-0.89100652,-0.91354546,-0.93358043,-0.95105652,-0.96592583,-0.97814760,-0.98768834,-0.99452190,-0.99862953,-1.00000000,-0.99862953,-0.99452190,-0.98768834,-0.97814760,-0.96592583,-0.95105652,-0.93358043,-0.91354546,-0.89100652,
-0.86602540,-0.83867057,-0.80901699,-0.77714596,-0.74314483,-0.70710678,-0.66913061,-0.62932039,-0.58778525,-0.54463904,-0.50000000,-0.45399050,-0.40673664,-0.35836795,-0.30901699,-0.25881905,-0.20791169,-0.15643447,-0.10452846,-0.05233596,
0.00000000,0.05233596,0.10452846,0.15643447,0.20791169,0.25881905,0.30901699,0.35836795,0.40673664,0.45399050,0.50000000,0.54463904,0.58778525,0.62932039,0.66913061,0.70710678,0.74314483,0.77714596,0.80901699,0.83867057,
0.86602540,0.89100652,0.91354546,0.93358043,0.95105652,0.96592583,0.97814760,0.98768834,0.99452190,0.99862953,1.00000000,0.99862953,0.99452190,0.98768834,0.97814760,0.96592583,0.95105652,0.93358043,0.91354546,0.89100652,
0.86602540,0.83867057,0.80901699,0.77714596,0.74314483,0.70710678,0.66913061,0.62932039,0.58778525,0.54463904,0.50000000,0.45399050,0.40673664,0.35836795,0.30901699,0.25881905,0.20791169,0.15643447,0.10452846,0.05233596,
0.00000000,-0.05233596,-0.10452846,-0.15643447,-0.20791169,-0.25881905,-0.30901699,-0.35836795,-0.40673664,-0.45399050,-0.50000000,-0.54463904,-0.58778525,-0.62932039,-0.66913061,-0.70710678,-0.74314483,-0.77714596,-0.80901699,-0.83867057,
-0.86602540,-0.89100652,-0.91354546,-0.93358043,-0.95105652,-0.96592583,-0.97814760,-0.98768834,-0.99452190,-0.99862953,-1.00000000,-0.99862953,-0.99452190,-0.98768834,-0.97814760,-0.96592583,-0.95105652,-0.93358043,-0.91354546,-0.89100652,
-0.86602540,-0.83867057,-0.80901699,-0.77714596,-0.74314483,-0.70710678,-0.66913061,-0.62932039,-0.58778525,-0.54463904,-0.50000000,-0.45399050,-0.40673664,-0.35836795,-0.30901699,-0.25881905,-0.20791169,-0.15643447,-0.10452846,-0.05233596,
0.00000000,0.05233596,0.10452846,0.15643447,0.20791169,0.25881905,0.30901699,0.35836795,0.40673664,0.45399050,0.50000000,0.54463904,0.58778525,0.62932039,0.66913061,0.70710678,0.74314483,0.77714596,0.80901699,0.83867057,
0.86602540,0.89100652,0.91354546,0.93358043,0.95105652,0.96592583,0.97814760,0.98768834,0.99452190,0.99862953,1.00000000,0.99862953,0.99452190,0.98768834,0.97814760,0.96592583,0.95105652,0.93358043,0.91354546,0.89100652,
0.86602540,0.83867057,0.80901699,0.77714596,0.74314483,0.70710678,0.66913061,0.62932039,0.58778525,0.54463904,0.50000000,0.45399050,0.40673664,0.35836795,0.30901699,0.25881905,0.20791169,0.15643447,0.10452846,0.05233596,
0.00000000,-0.05233596,-0.10452846,-0.15643447,-0.20791169,-0.25881905,-0.30901699,-0.35836795,-0.40673664,-0.45399050,-0.50000000,-0.54463904,-0.58778525,-0.62932039,-0.66913061,-0.70710678,-0.74314483,-0.77714596,-0.80901699,-0.83867057,
-0.86602540,-0.89100652,-0.91354546,-0.93358043,-0.95105652,-0.96592583,-0.97814760,-0.98768834,-0.99452190,-0.99862953,-1.00000000,-0.99862953,-0.99452190,-0.98768834,-0.97814760,-0.96592583,-0.95105652,-0.93358043,-0.91354546,-0.89100652,
-0.86602540,-0.83867057,-0.80901699,-0.77714596,-0.74314483,-0.70710678,-0.66913061,-0.62932039,-0.58778525,-0.54463904,-0.50000000,-0.45399050,-0.40673664,-0.35836795,-0.30901699,-0.25881905,-0.20791169,-0.15643447,-0.10452846,-0.05233596,
0.00000000,0.05233596,0.10452846,0.15643447,0.20791169,0.25881905,0.30901699,0.35836795,0.40673664,0.45399050,0.50000000,0.54463904,0.58778525,0.62932039,0.66913061,0.70710678,0.74314483,0.77714596,0.80901699,0.83867057,
0.86602540,0.89100652,0.91354546,0.93358043,0.95105652,0.96592583,0.97814760,0.98768834,0.99452190,0.99862953

};

/* USER CODE END PV */

void SystemClock_Config(void);
static void MX_I2C1_Init(void);
static void MX_GPIO_Init(void);
static void MX_DMA_Init(void);
static void MX_TIM5_Init(void);
static void MX_TIM2_Init(void);
static void MX_TIM3_Init(void);
static void MX_ADC1_Init(void);
static void MX_ADC3_Init(void);

/* USER CODE BEGIN 0 */
//__attribute__ ((section(".ccm_ram"))) uint8_t data[64][1024]  = {0};
/* USER CODE END 0 */

int main(void)
{
  /* USER CODE BEGIN 1 */

	DCPID.Kp = 50; 			/* Proportional --比例参数 */
	DCPID.Ki = 2;         	/* Integral  --积分参数*/
	DCPID.Kd = 0; 			/* Derivative     --微分参数*/
  /* USER CODE END 1 */

  /* MCU Configuration--------------------------------------------------------*/

  /* Reset of all peripherals, Initializes the Flash interface and the Systick. */
  HAL_Init();

  /* Configure the system clock */
  SystemClock_Config();

  /* Initialize all configured peripherals */
  MX_I2C1_Init();
  MX_GPIO_Init();
  MX_DMA_Init();
  MX_TIM5_Init();
  MX_TIM2_Init();
  MX_TIM3_Init();
  MX_ADC1_Init();
  MX_ADC3_Init();
  /* USER CODE BEGIN 2 */

//  HAL_I2C_Mem_Write(&hi2c1, ADDR_AT24C02_Write, 0, I2C_MEMADD_SIZE_16BIT,(uint8_t*)(&(PHASE1[0])),8, 1000);
//  HAL_Delay(1);

  HAL_I2C_Mem_Read(&hi2c1, ADDR_AT24C02_Read, 0, I2C_MEMADD_SIZE_16BIT,(uint8_t*)(&(PHASE[0])),8, 1000);

  HAL_TIM_PWM_Start(&htim2, TIM_CHANNEL_1);/*pwm波频�????????????????????????????????????????????????????????*/
  HAL_TIM_PWM_Start(&htim2, TIM_CHANNEL_2);
  HAL_TIM_PWM_Start(&htim2, TIM_CHANNEL_3);
  HAL_TIM_PWM_Start_IT(&htim2, TIM_CHANNEL_4);
  HAL_TIM_Base_Start_IT(&htim3);/*pid*/
  HAL_TIM_Base_Start(&htim5);/*计数时间*/

  HAL_ADC_Start_DMA(&hadc1, ADC_Value1, 10);
  HAL_ADC_Start_DMA(&hadc3, ADC_Value3, 10);

  arm_pid_init_f32(&DCPID, 1);

  LCD_init();

  /* USER CODE END 2 */

  /* Infinite loop */
  while (1)
  {

    /* USER CODE BEGIN 3 */

  	if( (HAL_GetTick()-MainTick)>300)
	{
  		HAL_I2C_Mem_Write(&hi2c1, ADDR_AT24C02_Write, 0, I2C_MEMADD_SIZE_16BIT,(uint8_t*)(&(PHASE[0])),8, 1000);
  	sprintf(show0,"1 %.4f",1.2*(((ADC_Value3[0])*1.0)/(ADC_Value1[0])*1.0));
  	sprintf(show1,"%d",(int)PHASE[0]);
  	sprintf(show2,"%d",COSCom2_plus);
  	sprintf(show3,"%f",COSCom2);

		/*
		sprintf(show2,"BT_V:%.3f",BT_VReal);
		sprintf(show3,"DC_V:%.3f",DC_VReal);
		sprintf(show4,"PW_V:%.3f",PW_VReal);
		sprintf(show5,"PW_C:%.3f",PW_CReal_1);
		*/
		LCD_write_String(0,0,show0);
		LCD_write_String(0,1,show1);
		LCD_write_String(0,2,show2);
		LCD_write_String(0,3,show3);
		LCD_write_String(0,4,show4);
		LCD_write_String(0,5,show5);
		HAL_GPIO_TogglePin(LED0_GPIO_Port, LED0_Pin);
		MainTick=HAL_GetTick();
	}

  }
  /* USER CODE END 3 */
}

void SystemClock_Config(void)
{
  RCC_OscInitTypeDef RCC_OscInitStruct = {0};
  RCC_ClkInitTypeDef RCC_ClkInitStruct = {0};

  /** Configure the main internal regulator output voltage
  */
  __HAL_RCC_PWR_CLK_ENABLE();
  __HAL_PWR_VOLTAGESCALING_CONFIG(PWR_REGULATOR_VOLTAGE_SCALE1);
  /** Initializes the RCC Oscillators according to the specified parameters
  * in the RCC_OscInitTypeDef structure.
  */
  RCC_OscInitStruct.OscillatorType = RCC_OSCILLATORTYPE_HSI;
  RCC_OscInitStruct.HSIState = RCC_HSI_ON;
  RCC_OscInitStruct.HSICalibrationValue = RCC_HSICALIBRATION_DEFAULT;
  RCC_OscInitStruct.PLL.PLLState = RCC_PLL_ON;
  RCC_OscInitStruct.PLL.PLLSource = RCC_PLLSOURCE_HSI;
  RCC_OscInitStruct.PLL.PLLM = 8;
  RCC_OscInitStruct.PLL.PLLN = 168;
  RCC_OscInitStruct.PLL.PLLP = RCC_PLLP_DIV2;
  RCC_OscInitStruct.PLL.PLLQ = 4;
  if (HAL_RCC_OscConfig(&RCC_OscInitStruct) != HAL_OK)
  {
    Error_Handler();
  }
  /** Initializes the CPU, AHB and APB buses clocks
  */
  RCC_ClkInitStruct.ClockType = RCC_CLOCKTYPE_HCLK|RCC_CLOCKTYPE_SYSCLK
                              |RCC_CLOCKTYPE_PCLK1|RCC_CLOCKTYPE_PCLK2;
  RCC_ClkInitStruct.SYSCLKSource = RCC_SYSCLKSOURCE_PLLCLK;
  RCC_ClkInitStruct.AHBCLKDivider = RCC_SYSCLK_DIV1;
  RCC_ClkInitStruct.APB1CLKDivider = RCC_HCLK_DIV4;
  RCC_ClkInitStruct.APB2CLKDivider = RCC_HCLK_DIV2;

  if (HAL_RCC_ClockConfig(&RCC_ClkInitStruct, FLASH_LATENCY_5) != HAL_OK)
  {
    Error_Handler();
  }
}

static void MX_ADC1_Init(void)
{

  ADC_ChannelConfTypeDef sConfig = {0};

  /** Configure the global features of the ADC (Clock, Resolution, Data Alignment and number of conversion)
  */
  hadc1.Instance = ADC1;
  hadc1.Init.ClockPrescaler = ADC_CLOCK_SYNC_PCLK_DIV6;
  hadc1.Init.Resolution = ADC_RESOLUTION_12B;
  hadc1.Init.ScanConvMode = ENABLE;
  hadc1.Init.ContinuousConvMode = ENABLE;
  hadc1.Init.DiscontinuousConvMode = DISABLE;
  hadc1.Init.ExternalTrigConvEdge = ADC_EXTERNALTRIGCONVEDGE_FALLING;
  hadc1.Init.ExternalTrigConv = ADC_EXTERNALTRIGCONV_T3_TRGO;
  hadc1.Init.DataAlign = ADC_DATAALIGN_RIGHT;
  hadc1.Init.NbrOfConversion = 1;
  hadc1.Init.DMAContinuousRequests = ENABLE;
  hadc1.Init.EOCSelection = ADC_EOC_SINGLE_CONV;
  if (HAL_ADC_Init(&hadc1) != HAL_OK)
  {
    Error_Handler();
  }
  /** Configure for the selected ADC regular channel its corresponding rank in the sequencer and its sample time.
  */
  sConfig.Channel = ADC_CHANNEL_VREFINT;
  sConfig.Rank = 1;
  sConfig.SamplingTime = ADC_SAMPLETIME_480CYCLES;
  if (HAL_ADC_ConfigChannel(&hadc1, &sConfig) != HAL_OK)
  {
    Error_Handler();
  }

}

static void MX_ADC3_Init(void)
{

  ADC_ChannelConfTypeDef sConfig = {0};

  /** Configure the global features of the ADC (Clock, Resolution, Data Alignment and number of conversion)
  */
  hadc3.Instance = ADC3;
  hadc3.Init.ClockPrescaler = ADC_CLOCK_SYNC_PCLK_DIV6;
  hadc3.Init.Resolution = ADC_RESOLUTION_12B;
  hadc3.Init.ScanConvMode = ENABLE;
  hadc3.Init.ContinuousConvMode = ENABLE;
  hadc3.Init.DiscontinuousConvMode = DISABLE;
  hadc3.Init.ExternalTrigConvEdge = ADC_EXTERNALTRIGCONVEDGE_FALLING;
  hadc3.Init.ExternalTrigConv = ADC_EXTERNALTRIGCONV_T3_TRGO;
  hadc3.Init.DataAlign = ADC_DATAALIGN_RIGHT;
  hadc3.Init.NbrOfConversion = 1;
  hadc3.Init.DMAContinuousRequests = ENABLE;
  hadc3.Init.EOCSelection = ADC_EOC_SINGLE_CONV;
  if (HAL_ADC_Init(&hadc3) != HAL_OK)
  {
    Error_Handler();
  }
  /** Configure for the selected ADC regular channel its corresponding rank in the sequencer and its sample time.
  */
  sConfig.Channel = ADC_CHANNEL_14;
  sConfig.Rank = 1;
  sConfig.SamplingTime = ADC_SAMPLETIME_480CYCLES;
  if (HAL_ADC_ConfigChannel(&hadc3, &sConfig) != HAL_OK)
  {
    Error_Handler();
  }

}

static void MX_I2C1_Init(void)
{

  hi2c1.Instance = I2C1;
  hi2c1.Init.ClockSpeed = 400000;
  hi2c1.Init.DutyCycle = I2C_DUTYCYCLE_2;
  hi2c1.Init.OwnAddress1 = 0;
  hi2c1.Init.AddressingMode = I2C_ADDRESSINGMODE_7BIT;
  hi2c1.Init.DualAddressMode = I2C_DUALADDRESS_DISABLE;
  hi2c1.Init.OwnAddress2 = 0;
  hi2c1.Init.GeneralCallMode = I2C_GENERALCALL_DISABLE;
  hi2c1.Init.NoStretchMode = I2C_NOSTRETCH_DISABLE;
  if (HAL_I2C_Init(&hi2c1) != HAL_OK)
  {
    Error_Handler();
  }

}

static void MX_TIM2_Init(void)
{

  TIM_ClockConfigTypeDef sClockSourceConfig = {0};
  TIM_MasterConfigTypeDef sMasterConfig = {0};
  TIM_OC_InitTypeDef sConfigOC = {0};

  htim2.Instance = TIM2;
  htim2.Init.Prescaler = 1-1;
  htim2.Init.CounterMode = TIM_COUNTERMODE_DOWN;
  htim2.Init.Period = 2800-1;
  htim2.Init.ClockDivision = TIM_CLOCKDIVISION_DIV1;
  htim2.Init.AutoReloadPreload = TIM_AUTORELOAD_PRELOAD_DISABLE;
  if (HAL_TIM_Base_Init(&htim2) != HAL_OK)
  {
    Error_Handler();
  }
  sClockSourceConfig.ClockSource = TIM_CLOCKSOURCE_INTERNAL;
  if (HAL_TIM_ConfigClockSource(&htim2, &sClockSourceConfig) != HAL_OK)
  {
    Error_Handler();
  }
  if (HAL_TIM_PWM_Init(&htim2) != HAL_OK)
  {
    Error_Handler();
  }
  sMasterConfig.MasterOutputTrigger = TIM_TRGO_UPDATE;
  sMasterConfig.MasterSlaveMode = TIM_MASTERSLAVEMODE_DISABLE;
  if (HAL_TIMEx_MasterConfigSynchronization(&htim2, &sMasterConfig) != HAL_OK)
  {
    Error_Handler();
  }
  sConfigOC.OCMode = TIM_OCMODE_PWM1;
  sConfigOC.Pulse = 1400-1;
  sConfigOC.OCPolarity = TIM_OCPOLARITY_HIGH;
  sConfigOC.OCFastMode = TIM_OCFAST_DISABLE;
  if (HAL_TIM_PWM_ConfigChannel(&htim2, &sConfigOC, TIM_CHANNEL_1) != HAL_OK)
  {
    Error_Handler();
  }
  sConfigOC.OCFastMode = TIM_OCFAST_ENABLE;
  if (HAL_TIM_PWM_ConfigChannel(&htim2, &sConfigOC, TIM_CHANNEL_2) != HAL_OK)
  {
    Error_Handler();
  }
  sConfigOC.Pulse = 100-1;
  sConfigOC.OCFastMode = TIM_OCFAST_DISABLE;
  if (HAL_TIM_PWM_ConfigChannel(&htim2, &sConfigOC, TIM_CHANNEL_3) != HAL_OK)
  {
    Error_Handler();
  }
  sConfigOC.Pulse = 1400-1;
  if (HAL_TIM_PWM_ConfigChannel(&htim2, &sConfigOC, TIM_CHANNEL_4) != HAL_OK)
  {
    Error_Handler();
  }
  HAL_TIM_MspPostInit(&htim2);

}

static void MX_TIM3_Init(void)
{

  TIM_ClockConfigTypeDef sClockSourceConfig = {0};
  TIM_MasterConfigTypeDef sMasterConfig = {0};

  htim3.Instance = TIM3;
  htim3.Init.Prescaler = 210-1;
  htim3.Init.CounterMode = TIM_COUNTERMODE_UP;
  htim3.Init.Period = 10000-1;
  htim3.Init.ClockDivision = TIM_CLOCKDIVISION_DIV1;
  htim3.Init.AutoReloadPreload = TIM_AUTORELOAD_PRELOAD_DISABLE;
  if (HAL_TIM_Base_Init(&htim3) != HAL_OK)
  {
    Error_Handler();
  }
  sClockSourceConfig.ClockSource = TIM_CLOCKSOURCE_INTERNAL;
  if (HAL_TIM_ConfigClockSource(&htim3, &sClockSourceConfig) != HAL_OK)
  {
    Error_Handler();
  }
  sMasterConfig.MasterOutputTrigger = TIM_TRGO_UPDATE;
  sMasterConfig.MasterSlaveMode = TIM_MASTERSLAVEMODE_DISABLE;
  if (HAL_TIMEx_MasterConfigSynchronization(&htim3, &sMasterConfig) != HAL_OK)
  {
    Error_Handler();
  }

}

static void MX_TIM5_Init(void)
{

  TIM_ClockConfigTypeDef sClockSourceConfig = {0};
  TIM_MasterConfigTypeDef sMasterConfig = {0};

  htim5.Instance = TIM5;
  htim5.Init.Prescaler = 84-1;
  htim5.Init.CounterMode = TIM_COUNTERMODE_UP;
  htim5.Init.Period = 4294967295;
  htim5.Init.ClockDivision = TIM_CLOCKDIVISION_DIV1;
  htim5.Init.AutoReloadPreload = TIM_AUTORELOAD_PRELOAD_DISABLE;
  if (HAL_TIM_Base_Init(&htim5) != HAL_OK)
  {
    Error_Handler();
  }
  sClockSourceConfig.ClockSource = TIM_CLOCKSOURCE_INTERNAL;
  if (HAL_TIM_ConfigClockSource(&htim5, &sClockSourceConfig) != HAL_OK)
  {
    Error_Handler();
  }
  sMasterConfig.MasterOutputTrigger = TIM_TRGO_RESET;
  sMasterConfig.MasterSlaveMode = TIM_MASTERSLAVEMODE_DISABLE;
  if (HAL_TIMEx_MasterConfigSynchronization(&htim5, &sMasterConfig) != HAL_OK)
  {
    Error_Handler();
  }

}

static void MX_DMA_Init(void)
{

  /* DMA controller clock enable */
  __HAL_RCC_DMA2_CLK_ENABLE();

}

static void MX_GPIO_Init(void)
{
  GPIO_InitTypeDef GPIO_InitStruct = {0};

  /* GPIO Ports Clock Enable */
  __HAL_RCC_GPIOE_CLK_ENABLE();
  __HAL_RCC_GPIOC_CLK_ENABLE();
  __HAL_RCC_GPIOF_CLK_ENABLE();
  __HAL_RCC_GPIOH_CLK_ENABLE();
  __HAL_RCC_GPIOA_CLK_ENABLE();
  __HAL_RCC_GPIOG_CLK_ENABLE();
  __HAL_RCC_GPIOB_CLK_ENABLE();

  /*Configure GPIO pin Output Level */
  HAL_GPIO_WritePin(LOCK_GPIO_Port, LOCK_Pin, GPIO_PIN_SET);

  /*Configure GPIO pin Output Level */
  HAL_GPIO_WritePin(COL4_GPIO_Port, COL4_Pin, GPIO_PIN_RESET);

  /*Configure GPIO pin Output Level */
  HAL_GPIO_WritePin(GPIOE, COL3_Pin|COL2_Pin|COL1_Pin|LCD5110RESET_Pin, GPIO_PIN_RESET);

  /*Configure GPIO pin Output Level */
  HAL_GPIO_WritePin(LCD5110SCE_GPIO_Port, LCD5110SCE_Pin, GPIO_PIN_SET);

  /*Configure GPIO pin Output Level */
  HAL_GPIO_WritePin(GPIOB, LCD5110SDIN_Pin|LCD5110DC_Pin|LCD5110SCLK_Pin, GPIO_PIN_RESET);

  /*Configure GPIO pin Output Level */
  HAL_GPIO_WritePin(GPIOG, LED0_Pin|LED1_Pin, GPIO_PIN_SET);

  /*Configure GPIO pins : Trig2_Pin Trig1_Pin */
  GPIO_InitStruct.Pin = Trig2_Pin|Trig1_Pin;
  GPIO_InitStruct.Mode = GPIO_MODE_IT_RISING;
  GPIO_InitStruct.Pull = GPIO_PULLDOWN;
  HAL_GPIO_Init(GPIOE, &GPIO_InitStruct);

  /*Configure GPIO pin : LOCK_Pin */
  GPIO_InitStruct.Pin = LOCK_Pin;
  GPIO_InitStruct.Mode = GPIO_MODE_OUTPUT_PP;
  GPIO_InitStruct.Pull = GPIO_NOPULL;
  GPIO_InitStruct.Speed = GPIO_SPEED_FREQ_LOW;
  HAL_GPIO_Init(LOCK_GPIO_Port, &GPIO_InitStruct);

  /*Configure GPIO pin : COL4_Pin */
  GPIO_InitStruct.Pin = COL4_Pin;
  GPIO_InitStruct.Mode = GPIO_MODE_OUTPUT_PP;
  GPIO_InitStruct.Pull = GPIO_PULLDOWN;
  GPIO_InitStruct.Speed = GPIO_SPEED_FREQ_LOW;
  HAL_GPIO_Init(COL4_GPIO_Port, &GPIO_InitStruct);

  /*Configure GPIO pins : COL3_Pin COL2_Pin COL1_Pin */
  GPIO_InitStruct.Pin = COL3_Pin|COL2_Pin|COL1_Pin;
  GPIO_InitStruct.Mode = GPIO_MODE_OUTPUT_PP;
  GPIO_InitStruct.Pull = GPIO_PULLDOWN;
  GPIO_InitStruct.Speed = GPIO_SPEED_FREQ_LOW;
  HAL_GPIO_Init(GPIOE, &GPIO_InitStruct);

  /*Configure GPIO pins : ROW1_Pin ROW2_Pin ROW3_Pin ROW4_Pin */
  GPIO_InitStruct.Pin = ROW1_Pin|ROW2_Pin|ROW3_Pin|ROW4_Pin;
  GPIO_InitStruct.Mode = GPIO_MODE_IT_FALLING;
  GPIO_InitStruct.Pull = GPIO_PULLUP;
  HAL_GPIO_Init(GPIOE, &GPIO_InitStruct);

  /*Configure GPIO pin : LCD5110RESET_Pin */
  GPIO_InitStruct.Pin = LCD5110RESET_Pin;
  GPIO_InitStruct.Mode = GPIO_MODE_OUTPUT_PP;
  GPIO_InitStruct.Pull = GPIO_NOPULL;
  GPIO_InitStruct.Speed = GPIO_SPEED_FREQ_VERY_HIGH;
  HAL_GPIO_Init(LCD5110RESET_GPIO_Port, &GPIO_InitStruct);

  /*Configure GPIO pin : LCD5110SCE_Pin */
  GPIO_InitStruct.Pin = LCD5110SCE_Pin;
  GPIO_InitStruct.Mode = GPIO_MODE_OUTPUT_PP;
  GPIO_InitStruct.Pull = GPIO_PULLUP;
  GPIO_InitStruct.Speed = GPIO_SPEED_FREQ_VERY_HIGH;
  HAL_GPIO_Init(LCD5110SCE_GPIO_Port, &GPIO_InitStruct);

  /*Configure GPIO pins : LCD5110SDIN_Pin LCD5110DC_Pin LCD5110SCLK_Pin */
  GPIO_InitStruct.Pin = LCD5110SDIN_Pin|LCD5110DC_Pin|LCD5110SCLK_Pin;
  GPIO_InitStruct.Mode = GPIO_MODE_OUTPUT_PP;
  GPIO_InitStruct.Pull = GPIO_NOPULL;
  GPIO_InitStruct.Speed = GPIO_SPEED_FREQ_VERY_HIGH;
  HAL_GPIO_Init(GPIOB, &GPIO_InitStruct);

  /*Configure GPIO pins : LED0_Pin LED1_Pin */
  GPIO_InitStruct.Pin = LED0_Pin|LED1_Pin;
  GPIO_InitStruct.Mode = GPIO_MODE_OUTPUT_PP;
  GPIO_InitStruct.Pull = GPIO_PULLUP;
  GPIO_InitStruct.Speed = GPIO_SPEED_FREQ_LOW;
  HAL_GPIO_Init(GPIOG, &GPIO_InitStruct);

  /* EXTI interrupt init*/
  HAL_NVIC_SetPriority(EXTI2_IRQn, 0, 0);
  HAL_NVIC_EnableIRQ(EXTI2_IRQn);

  HAL_NVIC_SetPriority(EXTI4_IRQn, 0, 0);
  HAL_NVIC_EnableIRQ(EXTI4_IRQn);

  HAL_NVIC_SetPriority(EXTI15_10_IRQn, 0, 0);
  HAL_NVIC_EnableIRQ(EXTI15_10_IRQn);

}

void Error_Handler(void)
{
  __disable_irq();
  while (1)
  {
  }
}

/************************ (C) COPYRIGHT STMicroelectronics *****END OF FILE****/
